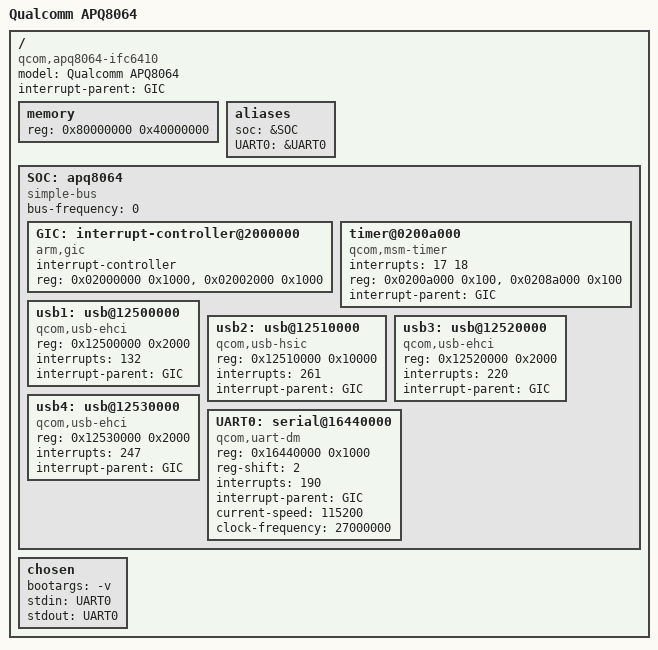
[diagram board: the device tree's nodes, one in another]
/*-
 * Copyright (c) 2013 Ganbold Tsagaankhuu <ganbold@gmail.com>
 * All rights reserved.
 *
 * Redistribution and use in source and binary forms, with or without
 * modification, are permitted provided that the following conditions
 * are met:
 * 1. Redistributions of source code must retain the above copyright
 *    notice, this list of conditions and the following disclaimer.
 * 2. Redistributions in binary form must reproduce the above copyright
 *    notice, this list of conditions and the following disclaimer in the
 *    documentation and/or other materials provided with the distribution.
 *
 * THIS SOFTWARE IS PROVIDED BY THE AUTHOR AND CONTRIBUTORS ``AS IS'' AND
 * ANY EXPRESS OR IMPLIED WARRANTIES, INCLUDING, BUT NOT LIMITED TO, THE
 * IMPLIED WARRANTIES OF MERCHANTABILITY AND FITNESS FOR A PARTICULAR PURPOSE
 * ARE DISCLAIMED.  IN NO EVENT SHALL THE AUTHOR OR CONTRIBUTORS BE LIABLE
 * FOR ANY DIRECT, INDIRECT, INCIDENTAL, SPECIAL, EXEMPLARY, OR CONSEQUENTIAL
 * DAMAGES (INCLUDING, BUT NOT LIMITED TO, PROCUREMENT OF SUBSTITUTE GOODS
 * OR SERVICES; LOSS OF USE, DATA, OR PROFITS; OR BUSINESS INTERRUPTION)
 * HOWEVER CAUSED AND ON ANY THEORY OF LIABILITY, WHETHER IN CONTRACT, STRICT
 * LIABILITY, OR TORT (INCLUDING NEGLIGENCE OR OTHERWISE) ARISING IN ANY WAY
 * OUT OF THE USE OF THIS SOFTWARE, EVEN IF ADVISED OF THE POSSIBILITY OF
 * SUCH DAMAGE.
 *
 * $FreeBSD$
 */

/dts-v1/;

/ {
	model = "Qualcomm APQ8064";
	compatible = "qcom,apq8064-ifc6410", "qcom,apq8064";
	#address-cells = <1>;
	#size-cells = <1>;

	interrupt-parent = <&GIC>;

	memory {
		device_type = "memory";
		reg = < 0x80000000 0x40000000 >; /* XXX: 1GB RAM for now */
	};

	aliases {
		soc = &SOC;
		UART0 = &UART0;
	}

	SOC: apq8064 {
		#address-cells = <1>;
		#size-cells = <1>;
		compatible = "simple-bus";
		ranges;
		bus-frequency = <0>;

		GIC: interrupt-controller@2000000 {
			compatible = "arm,gic";
			interrupt-controller;
			#interrupt-cells = <1>;
			reg = < 0x02000000 0x1000 >,
			      < 0x02002000 0x1000 >;
		};

// Following commented block is originally from linux
/*
		timer@200a000 {
			compatible = "qcom,kpss-timer", "qcom,msm-timer";
			interrupts = <1 1 0x301>,
				     <1 2 0x301>,
				     <1 3 0x301>;
			reg = <0x0200a000 0x100>;
			clock-frequency = <27000000>,
					  <32768>;
			cpu-offset = <0x80000>;
		};
*/

		timer@0200a000 {
			compatible = "qcom,msm-timer";
			interrupts = < 17 18 >;
			reg = 	<0x0200a000 0x100>,
				<0x0208a000 0x100>;
			interrupt-parent = <&GIC>;
		};

		usb1: usb@12500000 {
			compatible = "qcom,usb-ehci", "usb-ehci";
			reg = <0x12500000 0x2000>;
			interrupts = < 132 >;
			interrupt-parent = <&GIC>;
		};

		usb2: usb@12510000 {
			compatible = "qcom,usb-hsic", "usb-hsic";
			reg = <0x12510000 0x10000>;
			interrupts = < 261 >;
			interrupt-parent = <&GIC>;
		};

		usb3: usb@12520000 {
			compatible = "qcom,usb-ehci", "usb-ehci";
			reg = <0x12520000 0x2000>;
			interrupts = < 220 >;
			interrupt-parent = <&GIC>;
		};

		usb4: usb@12530000 {
			compatible = "qcom,usb-ehci", "usb-ehci";
			reg = <0x12530000 0x2000>;
			interrupts = < 247 >;
			interrupt-parent = <&GIC>;
		};

		UART0: serial@16440000 {
			status = "okay";
			compatible = "qcom,uart-dm";
			reg = <0x16440000 0x1000>;
			reg-shift = <2>;
			interrupts = <190>;
			interrupt-parent = <&GIC>;
			current-speed = <115200>;
			clock-frequency = < 27000000 >;
		};
	}
	chosen {
		bootargs = "-v";
		stdin = "UART0";
		stdout = "UART0";
	};
};
